# H5 register map
Vendor: Allwinner; Series: H5; File version: 0.1
CPU: 0, little endian, MPU, no FPU, 0 interrupt priority bits
Registers are 32-bit, read-write, reset 0x0 unless marked. A register's access mark holds for its fields unless they carry their own. Offsets are from the block's base; [hi:lo] are bit positions; lines under a group give offsets from that group; {n}, {i} and the like mark numbered series.

## High_Speed_Timer
Base 0x01C60000
0x00 HS_TMR_IRQ_EN_REG — HSTimer IRQ Enable Register
  [0] HS_TMR_INT_EN write-1-sets — High Speed Timer Interrupt Enable. 0: No effect 1: High Speed Timer Interval Value reached interrupt enable.
    0=No_effect; 1=High Speed Timer Interval Value reached interrupt enable
0x04 HS_TMR_IRQ_STAS_REG — HSTimer Status Register
  [0] HS_TMR_IRQ_PEND write-1-clears — High Speed Timer IRQ Pending. Setting 1 to the bit will clear it. 0: No effect 1: Pending. High Speed Timer Interval Value is reached.
    0=No_effect; 1=Pending. High Speed Timer Interval Value is reached.
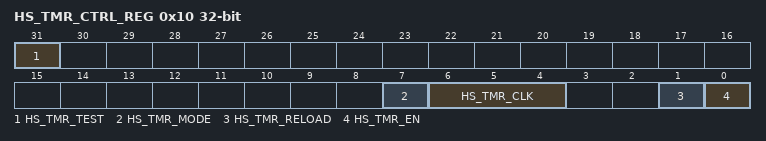
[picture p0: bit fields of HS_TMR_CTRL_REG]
0x10 HS_TMR_CTRL_REG — HSTimer Control Register
  [31] HS_TMR_TEST — High Speed Timer test mode. In test mode, the low register should be set to 0x1, the high register will down counter. The counter needs to be reloaded. 0: Normal mode 1: Test mode.
    0=Normal_mode; 1=Test mode
  [7] HS_TMR_MODE — High Speed Timer mode. 0: Continuous mode. When interval value reached, the timer will not disable automatically. 1: Single mode. When interval value reached, the timer will disable automatically.
    0=Continuous mode. When interval value reached, the timer will not disable automatically.; 1=Single mode. When interval value reached, the timer will disable automatically.
  [6:4] HS_TMR_CLK — Select the pre-scale of the High Speed Timer clock sources. 000: /1 001: /2 010: /4 011: /8 100: /16 101: / 110: / 111: /
    0=_slash_1 (/1); 1=_slash_2 (/2); 2=_slash_4 (/4); 3=_slash_8 (/8); 4=_slash_16 (/16)
  [1] HS_TMR_RELOAD write-1-sets — High Speed Timer reload. 0: No effect 1: Reload High Speed Timer Interval Value.
    0=No_effect; 1=Reload High Speed Timer Interval Value
  [0] HS_TMR_EN — High Speed Timer enable. 0: Stop/Pause 1: Start. If the timer is started, it will reload the interval value to internal register, and the current counter will count from interval value to 0. If the current counter does not reach the zero, the timer enable bit is set to , the u e t alue counter will pause. At least wait for 2 cycles, the start bit can be set to 1. In timer pause state, the interval value register can be modified. If the timer is started again, and the software hope the current value register to down-count from the new interval value, the reload bit and the enable bit should be set to 1 at the same time.
    0=Stop_slash_Pause (Stop/Pause); 1=Start. If the timer is started, it will reload the interval value to internal register, and the current counter will count from interval value to 0. If the current counter does not reach the zero, the timer enable bit is set to , the u e t alue counter will pause. At least wait for 2 cycles, the start bit can be set to 1. In timer pause state, the interval value register can be modified. If the timer is started again, and the software hope the current value register to down-count from the new interval value, the reload bit and the enable bit should be set to 1 at the same time.
0x14 HS_TMR_INTV_LO_REG reset not defined — HSTimer Interval Value Low Register
  [31:0] HS_TMR_INTV_VALUE_LO — High Speed Timer Interval Value [31:0].
0x18 HS_TMR_INTV_HI_REG reset not defined — HSTimer Interval Value High Register
  [23:0] HS_TMR_INTV_VALUE_HI — High Speed Timer Interval Value [55:32].
0x1C HS_TMR_CURNT_LO_REG reset not defined — HSTimer Current Value Low Register
  [31:0] HS_TMR_CUR_VALUE_LO — High Speed Timer Current Value [31:0].
0x20 HS_TMR_CURNT_HI_REG reset not defined — HSTimer Current Value High Register
  [23:0] HS_TMR_CUR_VALUE_HI — High Speed Timer Current Value [55:32].

## MSGBOX
Base 0x01C17000
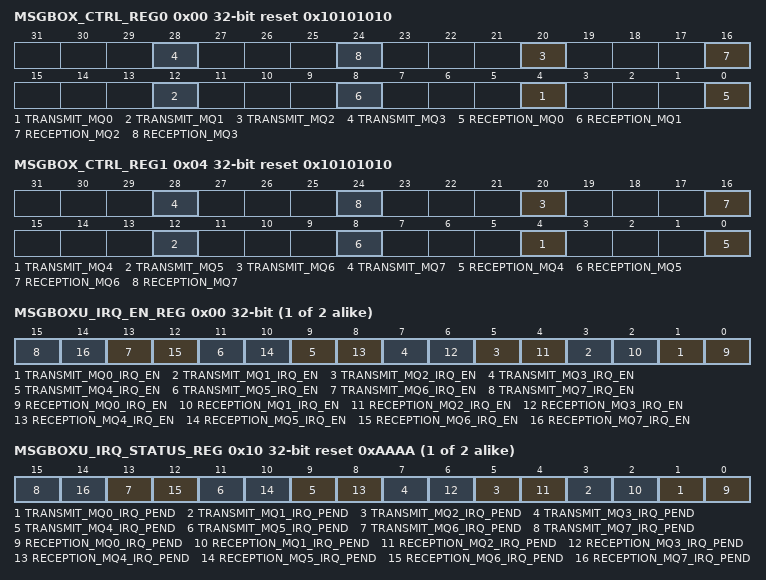
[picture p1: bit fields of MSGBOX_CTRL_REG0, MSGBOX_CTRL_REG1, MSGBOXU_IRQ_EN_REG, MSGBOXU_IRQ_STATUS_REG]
0x00 MSGBOX_CTRL_REG0 reset 0x10101010 — Message Queue Attribute Control Register 0
  [all] fields
    0=user0; 1=user1
  [8n+4] TRANSMIT_MQ{n} (n=0..3) — Message Queue {n} is a transmitter of user u. 0: user0 1: user1
  [8n] RECEPTION_MQ{n} (n=0..3) — Message Queue {n} is a receiver of user u. 0: user0 1: user1
0x04 MSGBOX_CTRL_REG1 reset 0x10101010 — Message Queue Attribute Control Register 1
  [all] fields
    0=user0; 1=user1
  [8n-28] TRANSMIT_MQ{n} (n=4..7) — Message Queue {n} is a transmitter of user u. 0: user0 1: user1
  [8n-32] RECEPTION_MQ{n} (n=4..7) — Message Queue {n} is a receiver of user u. 0: user0 1: user1
{0x40+0x20*i} _N[{i}] (i=0..1) group
  0x00 MSGBOXU_IRQ_EN_REG — (N=0,1) IRQ Enable for User U
    [2n+1] TRANSMIT_MQ{n}_IRQ_EN (n=0..7) — 0: Disable 1: Enable (It will notify user u by interrupt when Message Queue {n} is not full.)
      0=Disable; 1=Enable (It will notify user u by interrupt when Message Queue {n} is not full.)
    [2n] RECEPTION_MQ{n}_IRQ_EN (n=0..7) — 0: Disable 1: Enable (It will notify user u by interrupt when Message Queue {n} has received a new message.)
      0=Disable; 1=Enable (It will notify user u by interrupt when Message Queue {n} has received a new message.)
  0x10 MSGBOXU_IRQ_STATUS_REG reset 0xAAAA — (N=0,1) IRQ Status for User U
    [2n+1] TRANSMIT_MQ{n}_IRQ_PEND write-1-clears (n=0..7) — 0: No effect 1: Pending. This bit will be pending for user u when Message Queue {n} is not full. Setting 1 to this bit will clear it.
      0=No_effect; 1=Pending. This bit will be pending for user u when Message Queue {n} is not full. Setting 1 to this bit will clear it.
    [2n] RECEPTION_MQ{n}_IRQ_PEND write-1-clears (n=0..7) — 0: No effect 1: Pending. This bit will be pending for user u when Message Queue {n} has received a new message. Setting 1 to this bit will clear it.
      0=No_effect; 1=Pending. This bit will be pending for user u when Message Queue {n} has received a new message. Setting 1 to this bit will clear it.
{0x100+4i} _N[{i}] (i=0..7) group
  0x00 MSGBOXN_FIFO_STATUS_REG — (N = 0~7) FIFO Status for Message Queue N
    [0] FIFO_FULL_FLAG ro — 0: The Message FIFO queue is not full (space is available). 1: The Message FIFO queue is full. This FIFO status register has the status related to the message queue.
      0=not_full (The Message FIFO queue is not full (space is available).); 1=full (The Message FIFO queue is full. This FIFO status register has the status related to the message queue.)
  0x40 MSGBOXN_MSG_STATUS_REG — (N = 0~7) Message Status for Message Queue N
    [2:0] MSG_NUM ro — Number of unread messages in the message queue. Here, limit to four messages per message queue. 000: There is no message in the message FIFO queue. 001: There is 1 message in the message FIFO queue. 010: There are 2 messages in the message FIFO queue. 011: There are 3 messages in the message FIFO queue. 100: There are 4 messages in the message FIFO queue. 101~111:/
      0=no_message (There is no message in the message FIFO queue.); 1=There is 1 message in the message FIFO queue; 2=There are 2 messages in the message FIFO queue; 3=There are 3 messages in the message FIFO queue; 4=There are 4 messages in the message FIFO queue. 101~111:/
  0x80 MSGBOXN_MSG_REG — (N = 0~7) Message Register for Message Queue N
    [31:0] MESSAGE — The message register stores the next to be read message of the message FIFO queue. Reads remove the message from the FIFO queue.
